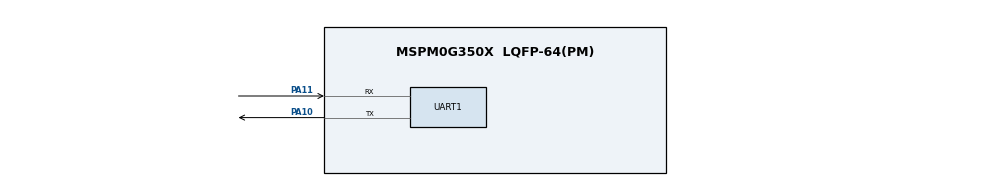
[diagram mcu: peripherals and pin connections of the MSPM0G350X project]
/**
 * @cliArgs --device "MSPM0G350X" --part "Default" --package "LQFP-64(PM)" --product "mspm0_sdk@2.10.00.04"
 * @versions {"tool":"1.26.2+4477"}
 */
const UART   = scripting.addModule("/ti/driverlib/UART", {}, false);
const UART1  = UART.addInstance();
const SYSCTL = scripting.addModule("/ti/driverlib/SYSCTL");

UART1.$name                      = "UART_0";
UART1.profile                    = "CONFIG_PROFILE_1";
UART1.peripheral.$assign         = "UART0";
UART1.targetBaudRate             = 9600;
UART1.enabledInterrupts          = ["RX"];
UART1.enableFIFO                 = false;
UART1.peripheral.rxPin.$assign   = "PA11";
UART1.peripheral.txPin.$assign   = "PA10";
const Board = scripting.addModule("/ti/driverlib/Board", {}, false);

SYSCTL.forceDefaultClkConfig = true;
Board.peripheral.$suggestSolution          = "DEBUGSS";
Board.peripheral.swclkPin.$suggestSolution = "PA20";
Board.peripheral.swdioPin.$suggestSolution = "PA19";
SYSCTL.peripheral.$suggestSolution         = "SYSCTL";
